AUTOSAR XML (schema 4-0-3)
package /ComponentTypes
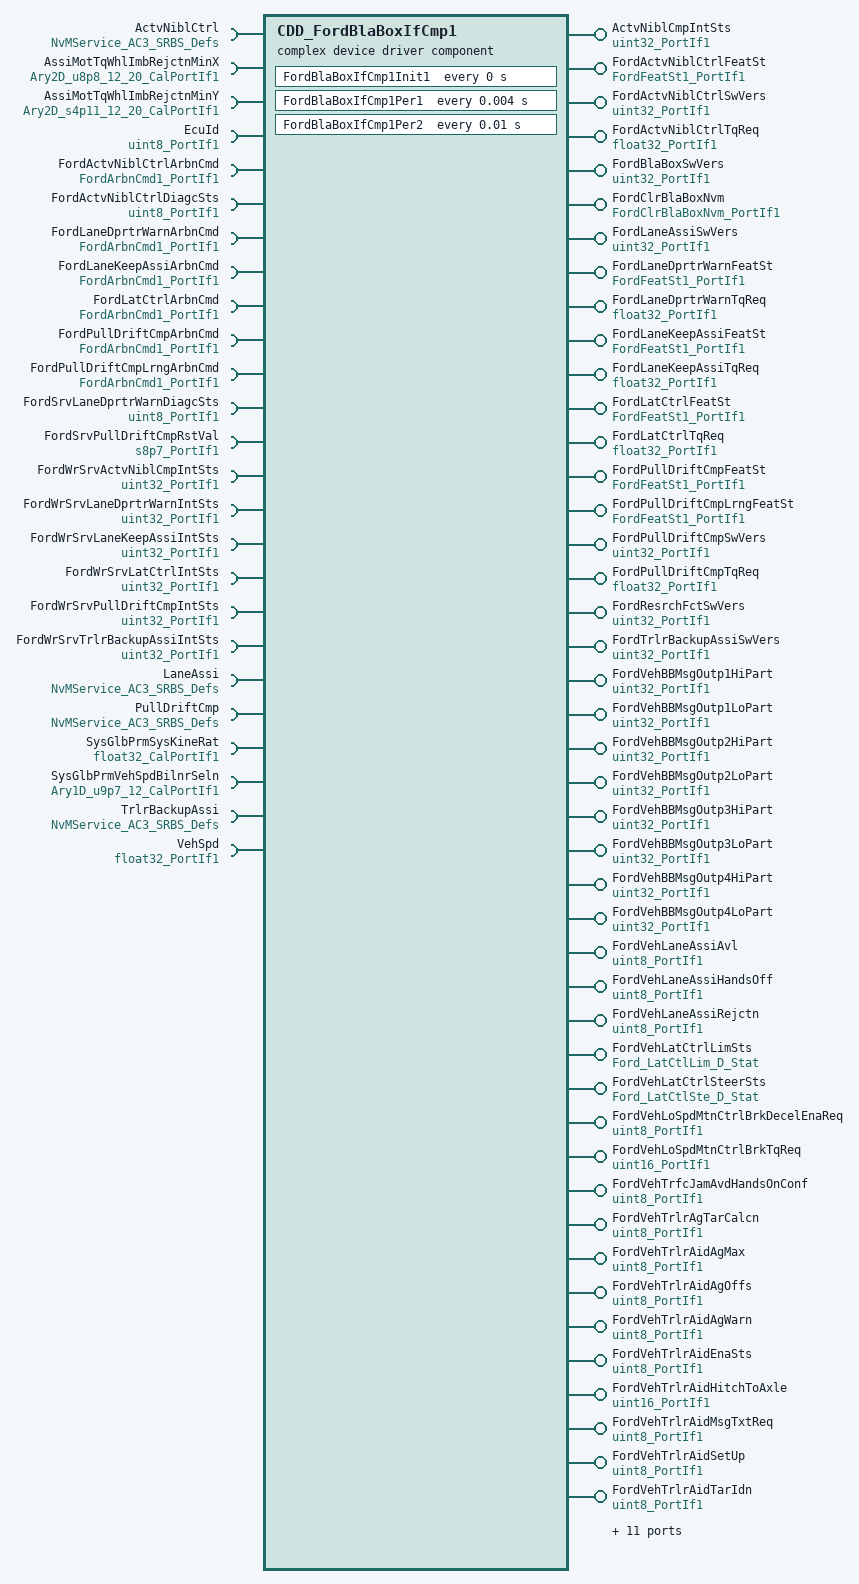
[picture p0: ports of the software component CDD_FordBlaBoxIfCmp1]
  complex device driver sw component type CDD_FordBlaBoxIfCmp1
    55 x provide port:
      ActvNiblCmpIntSts: nonqueued-sender-com-spec{data-element=Val, init-value=0}, provided-interface=uint32_PortIf1
      FordActvNiblCtrlFeatSt: nonqueued-sender-com-spec{data-element=Val, init-value=0}, provided-interface=FordFeatSt1_PortIf1
      FordActvNiblCtrlSwVers: nonqueued-sender-com-spec{data-element=Val, init-value=0}, provided-interface=uint32_PortIf1
      FordActvNiblCtrlTqReq: nonqueued-sender-com-spec{data-element=Val, init-value=0}, provided-interface=float32_PortIf1
      FordBlaBoxSwVers: nonqueued-sender-com-spec{data-element=Val, init-value=0}, provided-interface=uint32_PortIf1
      FordClrBlaBoxNvm: server-com-spec{operation=Oper, queue-length=1}, provided-interface=FordClrBlaBoxNvm_PortIf1
      FordLaneAssiSwVers: nonqueued-sender-com-spec{data-element=Val, init-value=0}, provided-interface=uint32_PortIf1
      FordLaneDprtrWarnFeatSt: nonqueued-sender-com-spec{data-element=Val, init-value=0}, provided-interface=FordFeatSt1_PortIf1
      FordLaneDprtrWarnTqReq: nonqueued-sender-com-spec{data-element=Val, init-value=0}, provided-interface=float32_PortIf1
      FordLaneKeepAssiFeatSt: nonqueued-sender-com-spec{data-element=Val, init-value=0}, provided-interface=FordFeatSt1_PortIf1
      FordLaneKeepAssiTqReq: nonqueued-sender-com-spec{data-element=Val, init-value=0}, provided-interface=float32_PortIf1
      FordLatCtrlFeatSt: nonqueued-sender-com-spec{data-element=Val, init-value=0}, provided-interface=FordFeatSt1_PortIf1
      FordLatCtrlTqReq: nonqueued-sender-com-spec{data-element=Val, init-value=0}, provided-interface=float32_PortIf1
      FordPullDriftCmpFeatSt: nonqueued-sender-com-spec{data-element=Val, init-value=0}, provided-interface=FordFeatSt1_PortIf1
      FordPullDriftCmpLrngFeatSt: nonqueued-sender-com-spec{data-element=Val, init-value=0}, provided-interface=FordFeatSt1_PortIf1
      FordPullDriftCmpSwVers: nonqueued-sender-com-spec{data-element=Val, init-value=0}, provided-interface=uint32_PortIf1
      FordPullDriftCmpTqReq: nonqueued-sender-com-spec{data-element=Val, init-value=0}, provided-interface=float32_PortIf1
      FordResrchFctSwVers: nonqueued-sender-com-spec{data-element=Val, init-value=0}, provided-interface=uint32_PortIf1
      FordTrlrBackupAssiSwVers: nonqueued-sender-com-spec{data-element=Val, init-value=0}, provided-interface=uint32_PortIf1
      FordVehBBMsgOutp1HiPart: nonqueued-sender-com-spec{data-element=Val, init-value=0}, provided-interface=uint32_PortIf1
      FordVehBBMsgOutp1LoPart: nonqueued-sender-com-spec{data-element=Val, init-value=0}, provided-interface=uint32_PortIf1
      FordVehBBMsgOutp2HiPart: nonqueued-sender-com-spec{data-element=Val, init-value=0}, provided-interface=uint32_PortIf1
      FordVehBBMsgOutp2LoPart: nonqueued-sender-com-spec{data-element=Val, init-value=0}, provided-interface=uint32_PortIf1
      FordVehBBMsgOutp3HiPart: nonqueued-sender-com-spec{data-element=Val, init-value=0}, provided-interface=uint32_PortIf1
      FordVehBBMsgOutp3LoPart: nonqueued-sender-com-spec{data-element=Val, init-value=0}, provided-interface=uint32_PortIf1
      FordVehBBMsgOutp4HiPart: nonqueued-sender-com-spec{data-element=Val, init-value=0}, provided-interface=uint32_PortIf1
      FordVehBBMsgOutp4LoPart: nonqueued-sender-com-spec{data-element=Val, init-value=0}, provided-interface=uint32_PortIf1
      FordVehLaneAssiAvl: nonqueued-sender-com-spec{data-element=Val, init-value=0}, provided-interface=uint8_PortIf1
      FordVehLaneAssiHandsOff: nonqueued-sender-com-spec{data-element=Val, init-value=1}, provided-interface=uint8_PortIf1
      FordVehLaneAssiRejctn: nonqueued-sender-com-spec{data-element=Val, init-value=0}, provided-interface=uint8_PortIf1
      FordVehLatCtrlLimSts: nonqueued-sender-com-spec=data-element=Ford_LatCtlLim_D_Stat, provided-interface=Ford_LatCtlLim_D_Stat
      FordVehLatCtrlSteerSts: nonqueued-sender-com-spec=data-element=Ford_LatCtlSte_D_Stat, provided-interface=Ford_LatCtlSte_D_Stat
      FordVehLoSpdMtnCtrlBrkDecelEnaReq: nonqueued-sender-com-spec{data-element=Val, init-value=0}, provided-interface=uint8_PortIf1
      FordVehLoSpdMtnCtrlBrkTqReq: nonqueued-sender-com-spec{data-element=Val, init-value=0}, provided-interface=uint16_PortIf1
      FordVehTrfcJamAvdHandsOnConf: nonqueued-sender-com-spec{data-element=Val, init-value=0}, provided-interface=uint8_PortIf1
      FordVehTrlrAgTarCalcn: nonqueued-sender-com-spec{data-element=Val, init-value=0}, provided-interface=uint8_PortIf1
      FordVehTrlrAidAgMax: nonqueued-sender-com-spec{data-element=Val, init-value=0}, provided-interface=uint8_PortIf1
      FordVehTrlrAidAgOffs: nonqueued-sender-com-spec{data-element=Val, init-value=0}, provided-interface=uint8_PortIf1
      FordVehTrlrAidAgWarn: nonqueued-sender-com-spec{data-element=Val, init-value=0}, provided-interface=uint8_PortIf1
      FordVehTrlrAidEnaSts: nonqueued-sender-com-spec{data-element=Val, init-value=0}, provided-interface=uint8_PortIf1
      FordVehTrlrAidHitchToAxle: nonqueued-sender-com-spec{data-element=Val, init-value=0}, provided-interface=uint16_PortIf1
      FordVehTrlrAidMsgTxtReq: nonqueued-sender-com-spec{data-element=Val, init-value=0}, provided-interface=uint8_PortIf1
      FordVehTrlrAidSetUp: nonqueued-sender-com-spec{data-element=Val, init-value=0}, provided-interface=uint8_PortIf1
      FordVehTrlrAidTarIdn: nonqueued-sender-com-spec{data-element=Val, init-value=0}, provided-interface=uint8_PortIf1
      FordVehTrlrAidTrlrIdn: nonqueued-sender-com-spec{data-element=Val, init-value=0}, provided-interface=uint8_PortIf1
      FordVehTrlrHitchLampReq: nonqueued-sender-com-spec{data-element=Val, init-value=0}, provided-interface=uint8_PortIf1
      FordVehVelMaxReqTrlrAid: nonqueued-sender-com-spec{data-element=Val, init-value=255}, provided-interface=uint8_PortIf1
      FordVehVelTrlrAidReq: nonqueued-sender-com-spec{data-element=Val, init-value=0}, provided-interface=uint8_PortIf1
      LaneDprtrWarnIntSts: nonqueued-sender-com-spec{data-element=Val, init-value=0}, provided-interface=uint32_PortIf1
      LaneKeepAssiIntSts: nonqueued-sender-com-spec{data-element=Val, init-value=0}, provided-interface=uint32_PortIf1
      LatCtrlIntSts: nonqueued-sender-com-spec{data-element=Val, init-value=0}, provided-interface=uint32_PortIf1
      PullDriftCmpIntSts: nonqueued-sender-com-spec{data-element=Val, init-value=0}, provided-interface=uint32_PortIf1
      SrvPullDriftCmpAct: nonqueued-sender-com-spec{data-element=Val, init-value=0}, provided-interface=s8p7_PortIf1
      SrvPullDriftCmpRstVal: nonqueued-sender-com-spec{data-element=Val, init-value=0}, provided-interface=s8p7_PortIf1
      TrlrBackupAssiIntSts: nonqueued-sender-com-spec{data-element=Val, init-value=0}, provided-interface=uint32_PortIf1
    25 x require port:
      ActvNiblCtrl: required-com-specs=[EraseBlock, GetErrorStatus, InvalidateNvBlock, ReadBlock, RestoreBlockDefaults, SetRamBlockStatus, WriteBlock], required-interface=NvMService_AC3_SRBS_Defs
      AssiMotTqWhlImbRejctnMinX: parameter-require-com-spec{init-value=[[0, 26, 53, 63, 74, 86, 98, 110, 123, 134, 146, 159, 170, 182, 194, 205, 256, 372, 1220, 2560], [0, 26, 78, 101, 123, 148, 171, 196, 220, 243, 267, 290, 315, 339, 362, 435, 563, 719, 1624, 2560], [0, 51, 80, 113, 145, 176, 205, 238, 266, 297, 330, 360, 391, 422, 452, 538, 717, 916, 2216, 2560], [0, 51, 80, 110, 146, 173, 205, 237, 266, 299, 330, 360, 392, 423, 452, 484, 640, 917, 947, 2560], [0, 51, 80, 111, 143, 177, 207, 238, 267, 300, 330, 359, 392, 422, 453, 483, 640, 819, 947, 2560], [0, 51, 79, 111, 139, 174, 206, 236, 267, 300, 334, 366, 396, 428, 460, 494, 640, 819, 972, 2560], [0, 51, 80, 106, 142, 175, 205, 239, 270, 300, 332, 366, 398, 429, 462, 494, 640, 819, 972, 2560], [0, 51, 100, 130, 163, 194, 229, 261, 291, 324, 355, 388, 420, 451, 483, 515, 640, 819, 998, 2560], [0, 51, 100, 130, 164, 196, 232, 260, 297, 327, 360, 396, 430, 462, 493, 527, 666, 819, 1024, 2560], [0, 51, 100, 130, 164, 196, 232, 260, 297, 327, 360, 396, 430, 462, 493, 527, 666, 819, 1024, 2560], [0, 51, 100, 130, 164, 196, 232, 260, 297, 327, 360, 396, 430, 462, 493, 527, 666, 819, 1024, 2560], [0, 51, 100, 130, 164, 196, 232, 260, 297, 327, 360, 396, 430, 462, 493, 527, 666, 819, 1024, 2560]], parameter=Ary2D}, required-interface=Ary2D_u8p8_12_20_CalPortIf1
      AssiMotTqWhlImbRejctnMinY: parameter-require-com-spec{init-value=[[0, 0, 48, 72, 104, 144, 192, 248, 312, 376, 448, 536, 616, 712, 816, 920, 1536, 3128, 17904, 17904], [0, 0, 64, 104, 152, 216, 288, 376, 472, 576, 696, 824, 968, 1120, 1280, 1761, 3072, 5120, 17904, 17904], [0, 0, 32, 80, 136, 200, 272, 360, 448, 552, 672, 792, 928, 1072, 1224, 1741, 3031, 4728, 17904, 17904], [0, 0, 32, 72, 128, 176, 240, 312, 384, 472, 560, 656, 760, 872, 984, 1112, 2048, 3568, 3792, 15632], [0, 0, 32, 72, 120, 176, 232, 296, 360, 440, 520, 600, 696, 792, 896, 1000, 1741, 2642, 3320, 13472], [0, 0, 32, 72, 112, 168, 224, 280, 344, 416, 496, 576, 656, 744, 840, 944, 1536, 2314, 3024, 11632], [0, 0, 32, 64, 112, 160, 208, 264, 320, 376, 440, 512, 584, 656, 736, 816, 1311, 1925, 2456, 9120], [0, 0, 48, 80, 120, 160, 208, 256, 304, 360, 416, 480, 544, 608, 680, 752, 1126, 1720, 2264, 8272], [0, 0, 48, 80, 120, 160, 208, 248, 304, 352, 408, 472, 536, 600, 664, 736, 1024, 1536, 2160, 7528], [0, 0, 48, 80, 120, 160, 208, 248, 304, 352, 408, 472, 536, 600, 664, 736, 1024, 1536, 2160, 7528], [0, 0, 48, 80, 120, 160, 208, 248, 304, 352, 408, 472, 536, 600, 664, 736, 1024, 1536, 2160, 7528], [0, 0, 48, 80, 120, 160, 208, 248, 304, 352, 408, 472, 536, 600, 664, 736, 1024, 1536, 2160, 7528]], parameter=Ary2D}, required-interface=Ary2D_s4p11_12_20_CalPortIf1
      EcuId: nonqueued-receiver-com-spec{data-element=Val, filter=data-filter-type=ALWAYS, init-value=0}, required-interface=uint8_PortIf1
      FordActvNiblCtrlArbnCmd: nonqueued-receiver-com-spec{data-element=Val, filter=data-filter-type=ALWAYS, init-value=0}, required-interface=FordArbnCmd1_PortIf1
      FordActvNiblCtrlDiagcSts: nonqueued-receiver-com-spec{data-element=Val, filter=data-filter-type=ALWAYS, init-value=0}, required-interface=uint8_PortIf1
      FordLaneDprtrWarnArbnCmd: nonqueued-receiver-com-spec{data-element=Val, filter=data-filter-type=ALWAYS, init-value=0}, required-interface=FordArbnCmd1_PortIf1
      FordLaneKeepAssiArbnCmd: nonqueued-receiver-com-spec{data-element=Val, filter=data-filter-type=ALWAYS, init-value=0}, required-interface=FordArbnCmd1_PortIf1
      FordLatCtrlArbnCmd: nonqueued-receiver-com-spec{data-element=Val, filter=data-filter-type=ALWAYS, init-value=0}, required-interface=FordArbnCmd1_PortIf1
      FordPullDriftCmpArbnCmd: nonqueued-receiver-com-spec{data-element=Val, filter=data-filter-type=ALWAYS, init-value=0}, required-interface=FordArbnCmd1_PortIf1
      FordPullDriftCmpLrngArbnCmd: nonqueued-receiver-com-spec{data-element=Val, filter=data-filter-type=ALWAYS, init-value=0}, required-interface=FordArbnCmd1_PortIf1
      FordSrvLaneDprtrWarnDiagcSts: nonqueued-receiver-com-spec{data-element=Val, filter=data-filter-type=ALWAYS, init-value=0}, required-interface=uint8_PortIf1
      FordSrvPullDriftCmpRstVal: nonqueued-receiver-com-spec{data-element=Val, filter=data-filter-type=ALWAYS, init-value=0}, required-interface=s8p7_PortIf1
      FordWrSrvActvNiblCmpIntSts: nonqueued-receiver-com-spec{data-element=Val, filter=data-filter-type=ALWAYS, init-value=0}, required-interface=uint32_PortIf1
      FordWrSrvLaneDprtrWarnIntSts: nonqueued-receiver-com-spec{data-element=Val, filter=data-filter-type=ALWAYS, init-value=0}, required-interface=uint32_PortIf1
      FordWrSrvLaneKeepAssiIntSts: nonqueued-receiver-com-spec{data-element=Val, filter=data-filter-type=ALWAYS, init-value=0}, required-interface=uint32_PortIf1
      FordWrSrvLatCtrlIntSts: nonqueued-receiver-com-spec{data-element=Val, filter=data-filter-type=ALWAYS, init-value=0}, required-interface=uint32_PortIf1
      FordWrSrvPullDriftCmpIntSts: nonqueued-receiver-com-spec{data-element=Val, filter=data-filter-type=ALWAYS, init-value=0}, required-interface=uint32_PortIf1
      FordWrSrvTrlrBackupAssiIntSts: nonqueued-receiver-com-spec{data-element=Val, filter=data-filter-type=ALWAYS, init-value=0}, required-interface=uint32_PortIf1
      LaneAssi: required-com-specs=[EraseBlock, GetErrorStatus, InvalidateNvBlock, ReadBlock, RestoreBlockDefaults, SetRamBlockStatus, WriteBlock], required-interface=NvMService_AC3_SRBS_Defs
      PullDriftCmp: required-com-specs=[EraseBlock, GetErrorStatus, InvalidateNvBlock, ReadBlock, RestoreBlockDefaults, SetRamBlockStatus, WriteBlock], required-interface=NvMService_AC3_SRBS_Defs
      SysGlbPrmSysKineRat: parameter-require-com-spec{init-value=22, parameter=Val}, required-interface=float32_CalPortIf1
      SysGlbPrmVehSpdBilnrSeln: parameter-require-com-spec{init-value=[0, 640, 1920, 3840, 7680, 10240, 12800, 15360, 19200, 23040, 25600, 28160], parameter=Ary1D}, required-interface=Ary1D_u9p7_12_CalPortIf1
      TrlrBackupAssi: required-com-specs=[EraseBlock, GetErrorStatus, InvalidateNvBlock, ReadBlock, RestoreBlockDefaults, SetRamBlockStatus, WriteBlock], required-interface=NvMService_AC3_SRBS_Defs
      VehSpd: nonqueued-receiver-com-spec{data-element=Val, filter=data-filter-type=ALWAYS, init-value=0}, required-interface=float32_PortIf1
    behavior CDD_FordBlaBoxIfCmp1_InternalBehavior
      ar-typed-per-instance-memorys:
        7 x data, all with sw-calibration-access=READ-ONLY:
          ActvNiblCtrl: type=Ary1D_u08_128
          LaneAssi: type=Ary1D_u08_256
          PullDriftCmp: type=Ary1D_u08_128
          PullDriftCmpFctCallSel: type=boolean
          TqOffsTbl: type=Ary2D_u8p8_12_20
          TrlrBackAssiFctCallSel: type=boolean
          TrlrBackupAssi: type=Ary1D_u08_512
      timing event CDD_FordBlaBoxIfCmp1_InitEvent: start-on-event=FordBlaBoxIfCmp1Init1, period=0
      timing event TMT_FordBlaBoxIfCmp1Per1: start-on-event=FordBlaBoxIfCmp1Per1, period=0.004
      timing event TMT_FordBlaBoxIfCmp1Per2: start-on-event=FordBlaBoxIfCmp1Per2, period=0.01
      operation invoked event OIT_FordClrBlaBoxNvm_Oper_FordClrBlaBoxNvm_Oper: start-on-event=FordClrBlaBoxNvm_Oper, operation=FordClrBlaBoxNvm.Oper
      port-api-options:
        enable-take-address=false, indirect-api=false, port=ActvNiblCmpIntSts
        enable-take-address=false, indirect-api=false, port=ActvNiblCtrl
        enable-take-address=false, indirect-api=false, port=AssiMotTqWhlImbRejctnMinX
        enable-take-address=false, indirect-api=false, port=AssiMotTqWhlImbRejctnMinY
        enable-take-address=false, indirect-api=false, port=EcuId
        enable-take-address=false, indirect-api=false, port=FordActvNiblCtrlArbnCmd
        enable-take-address=false, indirect-api=false, port=FordActvNiblCtrlDiagcSts
        enable-take-address=false, indirect-api=false, port=FordActvNiblCtrlFeatSt
        enable-take-address=false, indirect-api=false, port=FordActvNiblCtrlSwVers
        enable-take-address=false, indirect-api=false, port=FordActvNiblCtrlTqReq
        enable-take-address=false, indirect-api=false, port=FordBlaBoxSwVers
        enable-take-address=false, indirect-api=false, port=FordClrBlaBoxNvm
        enable-take-address=false, indirect-api=false, port=FordLaneAssiSwVers
        enable-take-address=false, indirect-api=false, port=FordLaneDprtrWarnArbnCmd
        enable-take-address=false, indirect-api=false, port=FordLaneDprtrWarnFeatSt
        enable-take-address=false, indirect-api=false, port=FordLaneDprtrWarnTqReq
        enable-take-address=false, indirect-api=false, port=FordLaneKeepAssiArbnCmd
        enable-take-address=false, indirect-api=false, port=FordLaneKeepAssiFeatSt
        enable-take-address=false, indirect-api=false, port=FordLaneKeepAssiTqReq
        enable-take-address=false, indirect-api=false, port=FordLatCtrlArbnCmd
        enable-take-address=false, indirect-api=false, port=FordLatCtrlFeatSt
        enable-take-address=false, indirect-api=false, port=FordLatCtrlTqReq
        enable-take-address=false, indirect-api=false, port=FordPullDriftCmpArbnCmd
        enable-take-address=false, indirect-api=false, port=FordPullDriftCmpFeatSt
        enable-take-address=false, indirect-api=false, port=FordPullDriftCmpLrngArbnCmd
        enable-take-address=false, indirect-api=false, port=FordPullDriftCmpLrngFeatSt
        enable-take-address=false, indirect-api=false, port=FordPullDriftCmpSwVers
        enable-take-address=false, indirect-api=false, port=FordPullDriftCmpTqReq
        enable-take-address=false, indirect-api=false, port=FordResrchFctSwVers
        enable-take-address=false, indirect-api=false, port=FordSrvLaneDprtrWarnDiagcSts
        enable-take-address=false, indirect-api=false, port=FordSrvPullDriftCmpRstVal
        enable-take-address=false, indirect-api=false, port=FordTrlrBackupAssiSwVers
        enable-take-address=false, indirect-api=false, port=FordVehBBMsgOutp1HiPart
        enable-take-address=false, indirect-api=false, port=FordVehBBMsgOutp1LoPart
        enable-take-address=false, indirect-api=false, port=FordVehBBMsgOutp2HiPart
        enable-take-address=false, indirect-api=false, port=FordVehBBMsgOutp2LoPart
        enable-take-address=false, indirect-api=false, port=FordVehBBMsgOutp3HiPart
        enable-take-address=false, indirect-api=false, port=FordVehBBMsgOutp3LoPart
        enable-take-address=false, indirect-api=false, port=FordVehBBMsgOutp4HiPart
        enable-take-address=false, indirect-api=false, port=FordVehBBMsgOutp4LoPart
        enable-take-address=false, indirect-api=false, port=FordVehLaneAssiAvl
        enable-take-address=false, indirect-api=false, port=FordVehLaneAssiHandsOff
        enable-take-address=false, indirect-api=false, port=FordVehLaneAssiRejctn
        enable-take-address=false, indirect-api=false, port=FordVehLatCtrlLimSts
        enable-take-address=false, indirect-api=false, port=FordVehLatCtrlSteerSts
        enable-take-address=false, indirect-api=false, port=FordVehLoSpdMtnCtrlBrkDecelEnaReq
        enable-take-address=false, indirect-api=false, port=FordVehLoSpdMtnCtrlBrkTqReq
        enable-take-address=false, indirect-api=false, port=FordVehTrfcJamAvdHandsOnConf
        enable-take-address=false, indirect-api=false, port=FordVehTrlrAgTarCalcn
        enable-take-address=false, indirect-api=false, port=FordVehTrlrAidAgMax
        enable-take-address=false, indirect-api=false, port=FordVehTrlrAidAgOffs
        enable-take-address=false, indirect-api=false, port=FordVehTrlrAidAgWarn
        enable-take-address=false, indirect-api=false, port=FordVehTrlrAidEnaSts
        enable-take-address=false, indirect-api=false, port=FordVehTrlrAidHitchToAxle
        enable-take-address=false, indirect-api=false, port=FordVehTrlrAidMsgTxtReq
        enable-take-address=false, indirect-api=false, port=FordVehTrlrAidSetUp
        enable-take-address=false, indirect-api=false, port=FordVehTrlrAidTarIdn
        enable-take-address=false, indirect-api=false, port=FordVehTrlrAidTrlrIdn
        enable-take-address=false, indirect-api=false, port=FordVehTrlrHitchLampReq
        enable-take-address=false, indirect-api=false, port=FordVehVelMaxReqTrlrAid
        enable-take-address=false, indirect-api=false, port=FordVehVelTrlrAidReq
        enable-take-address=false, indirect-api=false, port=FordWrSrvActvNiblCmpIntSts
        enable-take-address=false, indirect-api=false, port=FordWrSrvLaneDprtrWarnIntSts
        enable-take-address=false, indirect-api=false, port=FordWrSrvLaneKeepAssiIntSts
        enable-take-address=false, indirect-api=false, port=FordWrSrvLatCtrlIntSts
        enable-take-address=false, indirect-api=false, port=FordWrSrvPullDriftCmpIntSts
        enable-take-address=false, indirect-api=false, port=FordWrSrvTrlrBackupAssiIntSts
        enable-take-address=false, indirect-api=false, port=LaneAssi
        enable-take-address=false, indirect-api=false, port=LaneDprtrWarnIntSts
        enable-take-address=false, indirect-api=false, port=LaneKeepAssiIntSts
        enable-take-address=false, indirect-api=false, port=LatCtrlIntSts
        enable-take-address=false, indirect-api=false, port=PullDriftCmp
        enable-take-address=false, indirect-api=false, port=PullDriftCmpIntSts
        enable-take-address=false, indirect-api=false, port=SrvPullDriftCmpAct
        enable-take-address=false, indirect-api=false, port=SrvPullDriftCmpRstVal
        enable-take-address=false, indirect-api=false, port=SysGlbPrmSysKineRat
        enable-take-address=false, indirect-api=false, port=SysGlbPrmVehSpdBilnrSeln
        enable-take-address=false, indirect-api=false, port=TrlrBackupAssi
        enable-take-address=false, indirect-api=false, port=TrlrBackupAssiIntSts
        enable-take-address=false, indirect-api=false, port=VehSpd
      4 x runnable:
        FordBlaBoxIfCmp1Init1
          data-receive-point-by-arguments:
            17 x access:
              REC_EcuId_Val: accessed-variable=EcuId.Val
              REC_FordActvNiblCtrlArbnCmd_Val_1: accessed-variable=FordActvNiblCtrlArbnCmd.Val
              REC_FordActvNiblCtrlDiagcSts_Val: accessed-variable=FordActvNiblCtrlDiagcSts.Val
              REC_FordLaneDprtrWarnArbnCmd_Val_1: accessed-variable=FordLaneDprtrWarnArbnCmd.Val
              REC_FordLaneKeepAssiArbnCmd_Val_1: accessed-variable=FordLaneKeepAssiArbnCmd.Val
              REC_FordLatCtrlArbnCmd_Val_1: accessed-variable=FordLatCtrlArbnCmd.Val
              REC_FordPullDriftCmpArbnCmd_Val_1: accessed-variable=FordPullDriftCmpArbnCmd.Val
              REC_FordPullDriftCmpLrngArbnCmd_Val_1: accessed-variable=FordPullDriftCmpLrngArbnCmd.Val
              REC_FordSrvLaneDprtrWarnDiagcSts_Val: accessed-variable=FordSrvLaneDprtrWarnDiagcSts.Val
              REC_FordSrvPullDriftCmpRstVal_Val: accessed-variable=FordSrvPullDriftCmpRstVal.Val
              REC_FordWrSrvActvNiblCmpIntSts_Val: accessed-variable=FordWrSrvActvNiblCmpIntSts.Val
              REC_FordWrSrvLaneDprtrWarnIntSts_Val: accessed-variable=FordWrSrvLaneDprtrWarnIntSts.Val
              REC_FordWrSrvLaneKeepAssiIntSts_Val: accessed-variable=FordWrSrvLaneKeepAssiIntSts.Val
              REC_FordWrSrvLatCtrlIntSts_Val: accessed-variable=FordWrSrvLatCtrlIntSts.Val
              REC_FordWrSrvPullDriftCmpIntSts_Val: accessed-variable=FordWrSrvPullDriftCmpIntSts.Val
              REC_FordWrSrvTrlrBackupAssiIntSts_Val: accessed-variable=FordWrSrvTrlrBackupAssiIntSts.Val
              REC_VehSpd_Val: accessed-variable=VehSpd.Val
          data-send-points:
            54 x access:
              SEND_ActvNiblCmpIntSts_Val: accessed-variable=ActvNiblCmpIntSts.Val
              SEND_FordActvNiblCtrlFeatSt_Val_1: accessed-variable=FordActvNiblCtrlFeatSt.Val
              SEND_FordActvNiblCtrlSwVers_Val: accessed-variable=FordActvNiblCtrlSwVers.Val
              SEND_FordActvNiblCtrlTqReq_Val_1: accessed-variable=FordActvNiblCtrlTqReq.Val
              SEND_FordBlaBoxSwVers_Val: accessed-variable=FordBlaBoxSwVers.Val
              SEND_FordLaneAssiSwVers_Val: accessed-variable=FordLaneAssiSwVers.Val
              SEND_FordLaneDprtrWarnFeatSt_Val_1: accessed-variable=FordLaneDprtrWarnFeatSt.Val
              SEND_FordLaneDprtrWarnTqReq_Val_1: accessed-variable=FordLaneDprtrWarnTqReq.Val
              SEND_FordLaneKeepAssiFeatSt_Val_1: accessed-variable=FordLaneKeepAssiFeatSt.Val
              SEND_FordLaneKeepAssiTqReq_Val: accessed-variable=FordLaneKeepAssiTqReq.Val
              SEND_FordLatCtrlFeatSt_Val_1: accessed-variable=FordLatCtrlFeatSt.Val
              SEND_FordLatCtrlTqReq_Val_1: accessed-variable=FordLatCtrlTqReq.Val
              SEND_FordPullDriftCmpFeatSt_Val_1: accessed-variable=FordPullDriftCmpFeatSt.Val
              SEND_FordPullDriftCmpLrngFeatSt_Val_1: accessed-variable=FordPullDriftCmpLrngFeatSt.Val
              SEND_FordPullDriftCmpSwVers_Val: accessed-variable=FordPullDriftCmpSwVers.Val
              SEND_FordPullDriftCmpTqReq_Val_1: accessed-variable=FordPullDriftCmpTqReq.Val
              SEND_FordResrchFctSwVers_Val: accessed-variable=FordResrchFctSwVers.Val
              SEND_FordTrlrBackupAssiSwVers_Val: accessed-variable=FordTrlrBackupAssiSwVers.Val
              SEND_FordVehBBMsgOutp1HiPart_Val: accessed-variable=FordVehBBMsgOutp1HiPart.Val
              SEND_FordVehBBMsgOutp1LoPart_Val: accessed-variable=FordVehBBMsgOutp1LoPart.Val
              SEND_FordVehBBMsgOutp2HiPart_Val: accessed-variable=FordVehBBMsgOutp2HiPart.Val
              SEND_FordVehBBMsgOutp2LoPart_Val: accessed-variable=FordVehBBMsgOutp2LoPart.Val
              SEND_FordVehBBMsgOutp3HiPart_Val: accessed-variable=FordVehBBMsgOutp3HiPart.Val
              SEND_FordVehBBMsgOutp3LoPart_Val: accessed-variable=FordVehBBMsgOutp3LoPart.Val
              SEND_FordVehBBMsgOutp4HiPart_Val: accessed-variable=FordVehBBMsgOutp4HiPart.Val
              SEND_FordVehBBMsgOutp4LoPart_Val: accessed-variable=FordVehBBMsgOutp4LoPart.Val
              SEND_FordVehLaneAssiAvl_Val: accessed-variable=FordVehLaneAssiAvl.Val
              SEND_FordVehLaneAssiHandsOff_Val: accessed-variable=FordVehLaneAssiHandsOff.Val
              SEND_FordVehLaneAssiRejctn_Val: accessed-variable=FordVehLaneAssiRejctn.Val
              SEND_FordVehLatCtrlLimSts_Ford_LatCtlLim_D_Stat: accessed-variable=FordVehLatCtrlLimSts.Ford_LatCtlLim_D_Stat
              SEND_FordVehLatCtrlSteerSts_Ford_LatCtlSte_D_Stat: accessed-variable=FordVehLatCtrlSteerSts.Ford_LatCtlSte_D_Stat
              SEND_FordVehLoSpdMtnCtrlBrkDecelEnaReq_Val: accessed-variable=FordVehLoSpdMtnCtrlBrkDecelEnaReq.Val
              SEND_FordVehLoSpdMtnCtrlBrkTqReq_Val: accessed-variable=FordVehLoSpdMtnCtrlBrkTqReq.Val
              SEND_FordVehTrfcJamAvdHandsOnConf_Val: accessed-variable=FordVehTrfcJamAvdHandsOnConf.Val
              SEND_FordVehTrlrAgTarCalcn_Val: accessed-variable=FordVehTrlrAgTarCalcn.Val
              SEND_FordVehTrlrAidAgMax_Val: accessed-variable=FordVehTrlrAidAgMax.Val
              SEND_FordVehTrlrAidAgOffs_Val: accessed-variable=FordVehTrlrAidAgOffs.Val
              SEND_FordVehTrlrAidAgWarn_Val: accessed-variable=FordVehTrlrAidAgWarn.Val
              SEND_FordVehTrlrAidEnaSts_Val: accessed-variable=FordVehTrlrAidEnaSts.Val
              SEND_FordVehTrlrAidHitchToAxle_Val: accessed-variable=FordVehTrlrAidHitchToAxle.Val
              SEND_FordVehTrlrAidMsgTxtReq_Val: accessed-variable=FordVehTrlrAidMsgTxtReq.Val
              SEND_FordVehTrlrAidSetUp_Val: accessed-variable=FordVehTrlrAidSetUp.Val
              SEND_FordVehTrlrAidTarIdn_Val: accessed-variable=FordVehTrlrAidTarIdn.Val
              SEND_FordVehTrlrAidTrlrIdn_Val: accessed-variable=FordVehTrlrAidTrlrIdn.Val
              SEND_FordVehTrlrHitchLampReq_Val: accessed-variable=FordVehTrlrHitchLampReq.Val
              SEND_FordVehVelMaxReqTrlrAid_Val: accessed-variable=FordVehVelMaxReqTrlrAid.Val
              SEND_FordVehVelTrlrAidReq_Val: accessed-variable=FordVehVelTrlrAidReq.Val
              SEND_LaneDprtrWarnIntSts_Val: accessed-variable=LaneDprtrWarnIntSts.Val
              SEND_LaneKeepAssiIntSts_Val: accessed-variable=LaneKeepAssiIntSts.Val
              SEND_LatCtrlIntSts_Val: accessed-variable=LatCtrlIntSts.Val
              SEND_PullDriftCmpIntSts_Val: accessed-variable=PullDriftCmpIntSts.Val
              SEND_SrvPullDriftCmpAct_Val_1: accessed-variable=SrvPullDriftCmpAct.Val
              SEND_SrvPullDriftCmpRstVal_Val_1: accessed-variable=SrvPullDriftCmpRstVal.Val
              SEND_TrlrBackupAssiIntSts_Val: accessed-variable=TrlrBackupAssiIntSts.Val
          4 x sync call, all with timeout=0:
            SC_ActvNiblCtrl_SetRamBlockStatus: operation=ActvNiblCtrl.SetRamBlockStatus
            SC_LaneAssi_SetRamBlockStatus: operation=LaneAssi.SetRamBlockStatus
            SC_PullDriftCmp_SetRamBlockStatus: operation=PullDriftCmp.SetRamBlockStatus
            SC_TrlrBackupAssi_SetRamBlockStatus: operation=TrlrBackupAssi.SetRamBlockStatus
        FordBlaBoxIfCmp1Per1
          data-receive-point-by-arguments:
            17 x access:
              REC_FordActvNiblCtrlArbnCmd_Val_1: accessed-variable=FordActvNiblCtrlArbnCmd.Val
              REC_FordActvNiblCtrlDiagcSts_Val: accessed-variable=FordActvNiblCtrlDiagcSts.Val
              REC_FordLaneDprtrWarnArbnCmd_Val_1: accessed-variable=FordLaneDprtrWarnArbnCmd.Val
              REC_FordLaneKeepAssiArbnCmd_Val_1: accessed-variable=FordLaneKeepAssiArbnCmd.Val
              REC_FordLatCtrlArbnCmd_Val_1: accessed-variable=FordLatCtrlArbnCmd.Val
              REC_FordPullDriftCmpArbnCmd_Val_1: accessed-variable=FordPullDriftCmpArbnCmd.Val
              REC_FordPullDriftCmpLrngArbnCmd_Val_1: accessed-variable=FordPullDriftCmpLrngArbnCmd.Val
              REC_FordSrvLaneDprtrWarnDiagcSts_Val: accessed-variable=FordSrvLaneDprtrWarnDiagcSts.Val
              REC_FordSrvPullDriftCmpRstVal_Val: accessed-variable=FordSrvPullDriftCmpRstVal.Val
              REC_FordWrSrvActvNiblCmpIntSts_Val: accessed-variable=FordWrSrvActvNiblCmpIntSts.Val
              REC_FordWrSrvLaneDprtrWarnIntSts_Val: accessed-variable=FordWrSrvLaneDprtrWarnIntSts.Val
              REC_FordWrSrvLaneKeepAssiIntSts_Val: accessed-variable=FordWrSrvLaneKeepAssiIntSts.Val
              REC_FordWrSrvLatCtrlIntSts_Val: accessed-variable=FordWrSrvLatCtrlIntSts.Val
              REC_FordWrSrvPullDriftCmpIntSts_Val: accessed-variable=FordWrSrvPullDriftCmpIntSts.Val
              REC_FordWrSrvTrlrBackupAssiIntSts_Val: accessed-variable=FordWrSrvTrlrBackupAssiIntSts.Val
              REC_uint8_Port_Val: accessed-variable=EcuId.Val
              REC_VehSpd_Val: accessed-variable=VehSpd.Val
          data-send-points:
            54 x access:
              SEND_ActvNiblCmpIntSts_Val: accessed-variable=ActvNiblCmpIntSts.Val
              SEND_FordActvNiblCtrlFeatSt_Val_1: accessed-variable=FordActvNiblCtrlFeatSt.Val
              SEND_FordActvNiblCtrlSwVers_Val: accessed-variable=FordActvNiblCtrlSwVers.Val
              SEND_FordActvNiblCtrlTqReq_Val_1: accessed-variable=FordActvNiblCtrlTqReq.Val
              SEND_FordBlaBoxSwVers_Val: accessed-variable=FordBlaBoxSwVers.Val
              SEND_FordLaneAssiSwVers_Val: accessed-variable=FordLaneAssiSwVers.Val
              SEND_FordLaneDprtrWarnFeatSt_Val_1: accessed-variable=FordLaneDprtrWarnFeatSt.Val
              SEND_FordLaneDprtrWarnTqReq_Val_1: accessed-variable=FordLaneDprtrWarnTqReq.Val
              SEND_FordLaneKeepAssiFeatSt_Val_1: accessed-variable=FordLaneKeepAssiFeatSt.Val
              SEND_FordLaneKeepAssiTqReq_Val: accessed-variable=FordLaneKeepAssiTqReq.Val
              SEND_FordLatCtrlFeatSt_Val_1: accessed-variable=FordLatCtrlFeatSt.Val
              SEND_FordLatCtrlTqReq_Val_1: accessed-variable=FordLatCtrlTqReq.Val
              SEND_FordPullDriftCmpFeatSt_Val_1: accessed-variable=FordPullDriftCmpFeatSt.Val
              SEND_FordPullDriftCmpLrngFeatSt_Val_1: accessed-variable=FordPullDriftCmpLrngFeatSt.Val
              SEND_FordPullDriftCmpSwVers_Val: accessed-variable=FordPullDriftCmpSwVers.Val
              SEND_FordPullDriftCmpTqReq_Val_1: accessed-variable=FordPullDriftCmpTqReq.Val
              SEND_FordResrchFctSwVers_Val: accessed-variable=FordResrchFctSwVers.Val
              SEND_FordTrlrBackupAssiSwVers_Val: accessed-variable=FordTrlrBackupAssiSwVers.Val
              SEND_FordVehBBMsgOutp1HiPart_Val: accessed-variable=FordVehBBMsgOutp1HiPart.Val
              SEND_FordVehBBMsgOutp1LoPart_Val: accessed-variable=FordVehBBMsgOutp1LoPart.Val
              SEND_FordVehBBMsgOutp2HiPart_Val: accessed-variable=FordVehBBMsgOutp2HiPart.Val
              SEND_FordVehBBMsgOutp2LoPart_Val: accessed-variable=FordVehBBMsgOutp2LoPart.Val
              SEND_FordVehBBMsgOutp3HiPart_Val: accessed-variable=FordVehBBMsgOutp3HiPart.Val
              SEND_FordVehBBMsgOutp3LoPart_Val: accessed-variable=FordVehBBMsgOutp3LoPart.Val
              SEND_FordVehBBMsgOutp4HiPart_Val: accessed-variable=FordVehBBMsgOutp4HiPart.Val
              SEND_FordVehBBMsgOutp4LoPart_Val: accessed-variable=FordVehBBMsgOutp4LoPart.Val
              SEND_FordVehLaneAssiAvl_Val: accessed-variable=FordVehLaneAssiAvl.Val
              SEND_FordVehLaneAssiHandsOff_Val: accessed-variable=FordVehLaneAssiHandsOff.Val
              SEND_FordVehLaneAssiRejctn_Val: accessed-variable=FordVehLaneAssiRejctn.Val
              SEND_FordVehLatCtrlLimSts_Ford_LatCtlLim_D_Stat: accessed-variable=FordVehLatCtrlLimSts.Ford_LatCtlLim_D_Stat
              SEND_FordVehLatCtrlSteerSts_Ford_LatCtlSte_D_Stat: accessed-variable=FordVehLatCtrlSteerSts.Ford_LatCtlSte_D_Stat
              SEND_FordVehLoSpdMtnCtrlBrkDecelEnaReq_Val: accessed-variable=FordVehLoSpdMtnCtrlBrkDecelEnaReq.Val
              SEND_FordVehLoSpdMtnCtrlBrkTqReq_Val: accessed-variable=FordVehLoSpdMtnCtrlBrkTqReq.Val
              SEND_FordVehTrfcJamAvdHandsOnConf_Val: accessed-variable=FordVehTrfcJamAvdHandsOnConf.Val
              SEND_FordVehTrlrAgTarCalcn_Val: accessed-variable=FordVehTrlrAgTarCalcn.Val
              SEND_FordVehTrlrAidAgMax_Val: accessed-variable=FordVehTrlrAidAgMax.Val
              SEND_FordVehTrlrAidAgOffs_Val: accessed-variable=FordVehTrlrAidAgOffs.Val
              SEND_FordVehTrlrAidAgWarn_Val: accessed-variable=FordVehTrlrAidAgWarn.Val
              SEND_FordVehTrlrAidEnaSts_Val: accessed-variable=FordVehTrlrAidEnaSts.Val
              SEND_FordVehTrlrAidHitchToAxle_Val: accessed-variable=FordVehTrlrAidHitchToAxle.Val
              SEND_FordVehTrlrAidMsgTxtReq_Val: accessed-variable=FordVehTrlrAidMsgTxtReq.Val
              SEND_FordVehTrlrAidSetUp_Val: accessed-variable=FordVehTrlrAidSetUp.Val
              SEND_FordVehTrlrAidTarIdn_Val: accessed-variable=FordVehTrlrAidTarIdn.Val
              SEND_FordVehTrlrAidTrlrIdn_Val: accessed-variable=FordVehTrlrAidTrlrIdn.Val
              SEND_FordVehTrlrHitchLampReq_Val: accessed-variable=FordVehTrlrHitchLampReq.Val
              SEND_FordVehVelMaxReqTrlrAid_Val: accessed-variable=FordVehVelMaxReqTrlrAid.Val
              SEND_FordVehVelTrlrAidReq_Val: accessed-variable=FordVehVelTrlrAidReq.Val
              SEND_LaneDprtrWarnIntSts_Val: accessed-variable=LaneDprtrWarnIntSts.Val
              SEND_LaneKeepAssiIntSts_Val: accessed-variable=LaneKeepAssiIntSts.Val
              SEND_LatCtrlIntSts_Val: accessed-variable=LatCtrlIntSts.Val
              SEND_PullDriftCmpIntSts_Val: accessed-variable=PullDriftCmpIntSts.Val
              SEND_SrvPullDriftCmpAct_Val_1: accessed-variable=SrvPullDriftCmpAct.Val
              SEND_SrvPullDriftCmpRstVal_Val_1: accessed-variable=SrvPullDriftCmpRstVal.Val
              SEND_TrlrBackupAssiIntSts_Val: accessed-variable=TrlrBackupAssiIntSts.Val
        FordBlaBoxIfCmp1Per2
          data-receive-point-by-arguments:
            17 x access:
              REC_FordActvNiblCtrlArbnCmd_Val_1: accessed-variable=FordActvNiblCtrlArbnCmd.Val
              REC_FordActvNiblCtrlDiagcSts_Val: accessed-variable=FordActvNiblCtrlDiagcSts.Val
              REC_FordLaneDprtrWarnArbnCmd_Val_1: accessed-variable=FordLaneDprtrWarnArbnCmd.Val
              REC_FordLaneKeepAssiArbnCmd_Val_1: accessed-variable=FordLaneKeepAssiArbnCmd.Val
              REC_FordLatCtrlArbnCmd_Val_1: accessed-variable=FordLatCtrlArbnCmd.Val
              REC_FordPullDriftCmpArbnCmd_Val_1: accessed-variable=FordPullDriftCmpArbnCmd.Val
              REC_FordPullDriftCmpLrngArbnCmd_Val_1: accessed-variable=FordPullDriftCmpLrngArbnCmd.Val
              REC_FordSrvLaneDprtrWarnDiagcSts_Val: accessed-variable=FordSrvLaneDprtrWarnDiagcSts.Val
              REC_FordSrvPullDriftCmpRstVal_Val: accessed-variable=FordSrvPullDriftCmpRstVal.Val
              REC_FordWrSrvActvNiblCmpIntSts_Val: accessed-variable=FordWrSrvActvNiblCmpIntSts.Val
              REC_FordWrSrvLaneDprtrWarnIntSts_Val: accessed-variable=FordWrSrvLaneDprtrWarnIntSts.Val
              REC_FordWrSrvLaneKeepAssiIntSts_Val: accessed-variable=FordWrSrvLaneKeepAssiIntSts.Val
              REC_FordWrSrvLatCtrlIntSts_Val: accessed-variable=FordWrSrvLatCtrlIntSts.Val
              REC_FordWrSrvPullDriftCmpIntSts_Val: accessed-variable=FordWrSrvPullDriftCmpIntSts.Val
              REC_FordWrSrvTrlrBackupAssiIntSts_Val: accessed-variable=FordWrSrvTrlrBackupAssiIntSts.Val
              REC_uint8_Port_Val: accessed-variable=EcuId.Val
              REC_VehSpd_Val: accessed-variable=VehSpd.Val
          data-send-points:
            54 x access:
              SEND_ActvNiblCmpIntSts_Val: accessed-variable=ActvNiblCmpIntSts.Val
              SEND_FordActvNiblCtrlFeatSt_Val_1: accessed-variable=FordActvNiblCtrlFeatSt.Val
              SEND_FordActvNiblCtrlSwVers_Val: accessed-variable=FordActvNiblCtrlSwVers.Val
              SEND_FordActvNiblCtrlTqReq_Val_1: accessed-variable=FordActvNiblCtrlTqReq.Val
              SEND_FordBlaBoxSwVers_Val: accessed-variable=FordBlaBoxSwVers.Val
              SEND_FordLaneAssiSwVers_Val: accessed-variable=FordLaneAssiSwVers.Val
              SEND_FordLaneDprtrWarnFeatSt_Val_1: accessed-variable=FordLaneDprtrWarnFeatSt.Val
              SEND_FordLaneDprtrWarnTqReq_Val_1: accessed-variable=FordLaneDprtrWarnTqReq.Val
              SEND_FordLaneKeepAssiFeatSt_Val_1: accessed-variable=FordLaneKeepAssiFeatSt.Val
              SEND_FordLaneKeepAssiTqReq_Val: accessed-variable=FordLaneKeepAssiTqReq.Val
              SEND_FordLatCtrlFeatSt_Val_1: accessed-variable=FordLatCtrlFeatSt.Val
              SEND_FordLatCtrlTqReq_Val_1: accessed-variable=FordLatCtrlTqReq.Val
              SEND_FordPullDriftCmpFeatSt_Val_1: accessed-variable=FordPullDriftCmpFeatSt.Val
              SEND_FordPullDriftCmpLrngFeatSt_Val_1: accessed-variable=FordPullDriftCmpLrngFeatSt.Val
              SEND_FordPullDriftCmpSwVers_Val: accessed-variable=FordPullDriftCmpSwVers.Val
              SEND_FordPullDriftCmpTqReq_Val_1: accessed-variable=FordPullDriftCmpTqReq.Val
              SEND_FordResrchFctSwVers_Val: accessed-variable=FordResrchFctSwVers.Val
              SEND_FordTrlrBackupAssiSwVers_Val: accessed-variable=FordTrlrBackupAssiSwVers.Val
              SEND_FordVehBBMsgOutp1HiPart_Val: accessed-variable=FordVehBBMsgOutp1HiPart.Val
              SEND_FordVehBBMsgOutp1LoPart_Val: accessed-variable=FordVehBBMsgOutp1LoPart.Val
              SEND_FordVehBBMsgOutp2HiPart_Val: accessed-variable=FordVehBBMsgOutp2HiPart.Val
              SEND_FordVehBBMsgOutp2LoPart_Val: accessed-variable=FordVehBBMsgOutp2LoPart.Val
              SEND_FordVehBBMsgOutp3HiPart_Val: accessed-variable=FordVehBBMsgOutp3HiPart.Val
              SEND_FordVehBBMsgOutp3LoPart_Val: accessed-variable=FordVehBBMsgOutp3LoPart.Val
              SEND_FordVehBBMsgOutp4HiPart_Val: accessed-variable=FordVehBBMsgOutp4HiPart.Val
              SEND_FordVehBBMsgOutp4LoPart_Val: accessed-variable=FordVehBBMsgOutp4LoPart.Val
              SEND_FordVehLaneAssiAvl_Val: accessed-variable=FordVehLaneAssiAvl.Val
              SEND_FordVehLaneAssiHandsOff_Val: accessed-variable=FordVehLaneAssiHandsOff.Val
              SEND_FordVehLaneAssiRejctn_Val: accessed-variable=FordVehLaneAssiRejctn.Val
              SEND_FordVehLatCtrlLimSts_Ford_LatCtlLim_D_Stat: accessed-variable=FordVehLatCtrlLimSts.Ford_LatCtlLim_D_Stat
              SEND_FordVehLatCtrlSteerSts_Ford_LatCtlSte_D_Stat: accessed-variable=FordVehLatCtrlSteerSts.Ford_LatCtlSte_D_Stat
              SEND_FordVehLoSpdMtnCtrlBrkDecelEnaReq_Val: accessed-variable=FordVehLoSpdMtnCtrlBrkDecelEnaReq.Val
              SEND_FordVehLoSpdMtnCtrlBrkTqReq_Val: accessed-variable=FordVehLoSpdMtnCtrlBrkTqReq.Val
              SEND_FordVehTrfcJamAvdHandsOnConf_Val: accessed-variable=FordVehTrfcJamAvdHandsOnConf.Val
              SEND_FordVehTrlrAgTarCalcn_Val: accessed-variable=FordVehTrlrAgTarCalcn.Val
              SEND_FordVehTrlrAidAgMax_Val: accessed-variable=FordVehTrlrAidAgMax.Val
              SEND_FordVehTrlrAidAgOffs_Val: accessed-variable=FordVehTrlrAidAgOffs.Val
              SEND_FordVehTrlrAidAgWarn_Val: accessed-variable=FordVehTrlrAidAgWarn.Val
              SEND_FordVehTrlrAidEnaSts_Val: accessed-variable=FordVehTrlrAidEnaSts.Val
              SEND_FordVehTrlrAidHitchToAxle_Val: accessed-variable=FordVehTrlrAidHitchToAxle.Val
              SEND_FordVehTrlrAidMsgTxtReq_Val: accessed-variable=FordVehTrlrAidMsgTxtReq.Val
              SEND_FordVehTrlrAidSetUp_Val: accessed-variable=FordVehTrlrAidSetUp.Val
              SEND_FordVehTrlrAidTarIdn_Val: accessed-variable=FordVehTrlrAidTarIdn.Val
              SEND_FordVehTrlrAidTrlrIdn_Val: accessed-variable=FordVehTrlrAidTrlrIdn.Val
              SEND_FordVehTrlrHitchLampReq_Val: accessed-variable=FordVehTrlrHitchLampReq.Val
              SEND_FordVehVelMaxReqTrlrAid_Val: accessed-variable=FordVehVelMaxReqTrlrAid.Val
              SEND_FordVehVelTrlrAidReq_Val: accessed-variable=FordVehVelTrlrAidReq.Val
              SEND_LaneDprtrWarnIntSts_Val: accessed-variable=LaneDprtrWarnIntSts.Val
              SEND_LaneKeepAssiIntSts_Val: accessed-variable=LaneKeepAssiIntSts.Val
              SEND_LatCtrlIntSts_Val: accessed-variable=LatCtrlIntSts.Val
              SEND_PullDriftCmpIntSts_Val: accessed-variable=PullDriftCmpIntSts.Val
              SEND_SrvPullDriftCmpAct_Val_1: accessed-variable=SrvPullDriftCmpAct.Val
              SEND_SrvPullDriftCmpRstVal_Val_1: accessed-variable=SrvPullDriftCmpRstVal.Val
              SEND_TrlrBackupAssiIntSts_Val: accessed-variable=TrlrBackupAssiIntSts.Val
        FordClrBlaBoxNvm_Oper
          4 x sync call, all with timeout=0:
            SC_ActvNiblCtrl_SetRamBlockStatus: operation=ActvNiblCtrl.SetRamBlockStatus
            SC_LaneAssi_SetRamBlockStatus: operation=LaneAssi.SetRamBlockStatus
            SC_PullDriftCmp_SetRamBlockStatus: operation=PullDriftCmp.SetRamBlockStatus
            SC_TrlrBackupAssi_SetRamBlockStatus: operation=TrlrBackupAssi.SetRamBlockStatus
      4 x swc service dependency:
        NvmActvNiblCtrl: assigned-ports=role-based-port-assignment={port-prototype=ActvNiblCtrl, role=NvMService_AC3_SRBS_Defs}
          assigned-datas:
            role=ramBlock, used-data-element=ActvNiblCtrl
            role=defaultValue, used-parameter-element=ActvNiblCtrlDft
          service-needs:
            nv block needs NvmActvNiblCtrl: readonly=false, reliability=ERROR-DETECTION, restore-at-start=true, store-at-shutdown=true, write-only-once=false
        NvmLaneAssi: assigned-datas=[{role=ramBlock, used-data-element=LaneAssi}, {role=defaultValue, used-parameter-element=LaneAssiDft}], assigned-ports=role-based-port-assignment={port-prototype=LaneAssi, role=NvMService_AC3_SRBS_Defs}
          service-needs:
            nv block needs NvmLaneAssi: readonly=false, reliability=ERROR-DETECTION, restore-at-start=true, store-at-shutdown=true, write-only-once=false
        NvmPullDriftCmp: assigned-ports=role-based-port-assignment={port-prototype=PullDriftCmp, role=NvMService_AC3_SRBS_Defs}
          assigned-datas:
            role=ramBlock, used-data-element=PullDriftCmp
            role=defaultValue, used-parameter-element=PullDriftCmpDft
          service-needs:
            nv block needs NvmPullDriftCmp: readonly=false, reliability=ERROR-DETECTION, restore-at-start=true, store-at-shutdown=true, write-only-once=false
        NvmTrlrBackupAssi: assigned-ports=role-based-port-assignment={port-prototype=TrlrBackupAssi, role=NvMService_AC3_SRBS_Defs}
          assigned-datas:
            role=ramBlock, used-data-element=TrlrBackupAssi
            role=defaultValue, used-parameter-element=TrlrBackupAssiDft
          service-needs:
            nv block needs NvmTrlrBackupAssi: readonly=false, reliability=ERROR-DETECTION, resistant-to-changed-sw=true, restore-at-start=true, store-at-shutdown=true, write-only-once=false
      shared-parameters:
        4 x parameter data prototype, all with sw-calibration-access=READ-WRITE:
          ActvNiblCtrlDft: type=Ary1D_u08_128, init-value=128 x 0
          LaneAssiDft: type=Ary1D_u08_256, init-value=256 x 0
          PullDriftCmpDft: type=Ary1D_u08_128, init-value=128 x 0
          TrlrBackupAssiDft: type=Ary1D_u08_512, init-value=512 x 0
  swc implementation CDD_FordBlaBoxIfCmp1_Implementation: behavior=CDD_FordBlaBoxIfCmp1_InternalBehavior
    code-descriptors:
      code Default: artifact-descriptors=autosar-engineering-object={short-label=Default, category=SWSRC}
